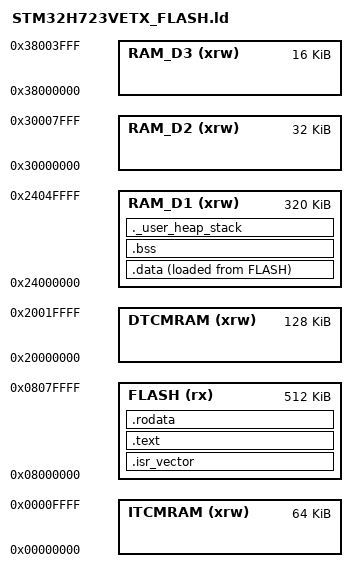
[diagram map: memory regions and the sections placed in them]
/* Entry Point */
ENTRY(Reset_Handler)

/* Highest address of the user mode stack */
_estack = ORIGIN(RAM_D1) + LENGTH(RAM_D1);    /* end of RAM */
/* Generate a link error if heap and stack don't fit into RAM */
_Min_Heap_Size = 0x200;      /* required amount of heap  (n-1)=0x200*/
_Min_Stack_Size = 0x400;     /* required amount of stack  (n-1)=0x400*/

/* Specify the memory areas */
MEMORY
{
  ITCMRAM (xrw)    : ORIGIN = 0x00000000,   LENGTH = 64K
  DTCMRAM (xrw)    : ORIGIN = 0x20000000,   LENGTH = 128K

  /* First four sectors (512KB) for program storage */
  FLASH    (rx)    : ORIGIN = 0x08000000,   LENGTH = 512K

  RAM_D1  (xrw)    : ORIGIN = 0x24000000,   LENGTH = 320K
  RAM_D2  (xrw)    : ORIGIN = 0x30000000,   LENGTH = 32K
  RAM_D3  (xrw)    : ORIGIN = 0x38000000,   LENGTH = 16K
}

/* Define output sections */
SECTIONS
{
  /* The startup code goes first into FLASH */
  .isr_vector :
  {
    . = ALIGN(4);
    KEEP(*(.isr_vector)) /* Startup code */
    . = ALIGN(4);
  } >FLASH

  /* The program code and other data goes into FLASH */
  .text :
  {
    . = ALIGN(4);
    *(.text)           
    *(.text*)          
    *(.glue_7)         
    *(.glue_7t)        
    *(.eh_frame)

    KEEP (*(.init))
    KEEP (*(.fini))

    . = ALIGN(4);
    _etext = .;        
  } >FLASH

  /* Constant data goes into FLASH */
  .rodata :
  {
    . = ALIGN(4);
    *(.rodata)         
    *(.rodata*)        
    . = ALIGN(4);
  } >FLASH

  /* Used by the startup to initialize data */
  _sidata = LOADADDR(.data);

  /* Initialized data sections goes into RAM, load LMA copy after code */
  .data :
  {
    . = ALIGN(4);
    _sdata = .;        
    *(.data)           
    *(.data*)          
    *(.RamFunc)        
    *(.RamFunc*)       

    . = ALIGN(4);
    _edata = .;        
  } >RAM_D1 AT> FLASH

  /* Uninitialized data section */
  . = ALIGN(4);
  .bss :
  {
    _sbss = .;        
    __bss_start__ = _sbss;
    *(.bss)
    *(.bss*)
    *(COMMON)

    . = ALIGN(4);
    _ebss = .;        
    __bss_end__ = _ebss;
  } >RAM_D1

  /* User_heap_stack section, used to check that there is enough RAM left */
  ._user_heap_stack :
  {
    . = ALIGN(8);
    PROVIDE ( end = . );
    PROVIDE ( _end = . );
    . = . + _Min_Heap_Size;
    . = . + _Min_Stack_Size;
    . = ALIGN(8);
  } >RAM_D1

  /* Remove information from the standard libraries */
  /DISCARD/ :
  {
    libc.a ( * )
    libm.a ( * )
    libgcc.a ( * )
  }

  .ARM.attributes 0 : { *(.ARM.attributes) }
}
